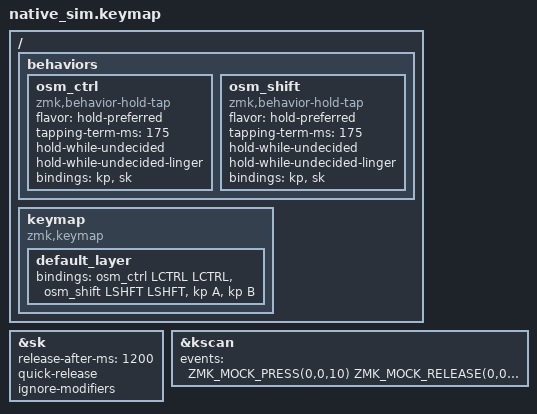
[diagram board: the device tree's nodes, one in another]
#include <behaviors.dtsi>
#include <dt-bindings/zmk/keys.h>
#include <dt-bindings/zmk/kscan_mock.h>

/ {
    behaviors {
        osm_ctrl: osm_ctrl {
            compatible = "zmk,behavior-hold-tap";
            #binding-cells = <2>;
            flavor = "hold-preferred";
            tapping-term-ms = <175>;
            hold-while-undecided;
            hold-while-undecided-linger;
            bindings = <&kp>, <&sk>;
        };

        osm_shift: osm_shift {
            compatible = "zmk,behavior-hold-tap";
            #binding-cells = <2>;
            flavor = "hold-preferred";
            tapping-term-ms = <175>;
            hold-while-undecided;
            hold-while-undecided-linger;
            bindings = <&kp>, <&sk>;
        };
    };

    keymap {
        compatible = "zmk,keymap";

        default_layer {
            bindings = <&osm_ctrl LCTRL LCTRL &osm_shift LSHFT LSHFT &kp A &kp B>;
        };
    };
};

&sk {
    release-after-ms = <1200>;
    quick-release;
    ignore-modifiers;
};

&kscan {
    events = <
        ZMK_MOCK_PRESS(0,0,10)
        ZMK_MOCK_RELEASE(0,0,10)
        ZMK_MOCK_PRESS(0,2,10)
        ZMK_MOCK_RELEASE(0,2,10)

        ZMK_MOCK_PRESS(0,0,200)
        ZMK_MOCK_RELEASE(0,0,10)
        ZMK_MOCK_PRESS(0,3,10)
        ZMK_MOCK_RELEASE(0,3,10)

        ZMK_MOCK_PRESS(0,0,200)
        ZMK_MOCK_PRESS(0,2,10)
        ZMK_MOCK_RELEASE(0,2,10)
        ZMK_MOCK_PRESS(0,3,10)
        ZMK_MOCK_RELEASE(0,3,10)
        ZMK_MOCK_RELEASE(0,0,10)

        ZMK_MOCK_PRESS(0,0,10)
        ZMK_MOCK_RELEASE(0,0,10)
        ZMK_MOCK_PRESS(0,1,10)
        ZMK_MOCK_RELEASE(0,1,10)
        ZMK_MOCK_PRESS(0,2,10)
        ZMK_MOCK_RELEASE(0,2,10)
    >;
};
